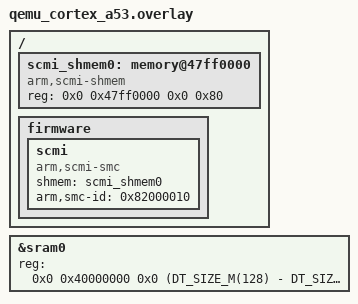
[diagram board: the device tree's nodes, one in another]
/*
 * Copyright The Zephyr Project Contributors
 * SPDX-License-Identifier: Apache-2.0
 */

#include <mem.h>

/* Take the last 64 KiB of RAM away from the kernel for an SCMI shmem area */
&sram0 {
	reg = <0x0 0x40000000 0x0 (DT_SIZE_M(128) - DT_SIZE_K(64))>;
};

/ {
	scmi_shmem0: memory@47ff0000 {
		compatible = "arm,scmi-shmem";
		reg = <0x0 0x47ff0000 0x0 0x80>;
	};

	/*
	 * The SCMI headers need a transport. No protocol is declared, so the
	 * SMC doorbell is never rung.
	 */
	firmware {
		scmi {
			compatible = "arm,scmi-smc";
			shmem = <&scmi_shmem0>;
			arm,smc-id = <0x82000010>;
			#address-cells = <1>;
			#size-cells = <0>;
		};
	};
};
